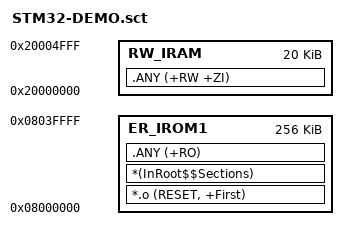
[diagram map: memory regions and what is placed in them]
; *************************************************************
; *** Scatter-Loading Description File generated by uVision ***
; *************************************************************

LR_IROM1 0x08000000 0x00040000  {    ; load region size_region
  ER_IROM1 0x08000000 0x00040000  {  ; load address = execution address
   *.o (RESET, +First)
   *(InRoot$$Sections)
   .ANY (+RO)
  }
 ; RW_IRAM1 0x20000000 0x0000C000  {  ; RW data
 ;  .ANY (+RW +ZI)
 ; }

 ; RW_IRAM1 0x20000000 0x00002800  {  ; RW data		   0x0000C000
 ;  .ANY (+RW +ZI)
 ; }
  RW_IRAM 0x20000000 0x00005000  {  ; RW data
   .ANY (+RW +ZI)
  ; stm32f10x_flash.o(+RO,+RW,+ZI)
 ;  stm32f10x_iwdg.o(+RO,+RW,+ZI)
  ; opflash.o(+RO,+RW,+ZI)

  }
}

